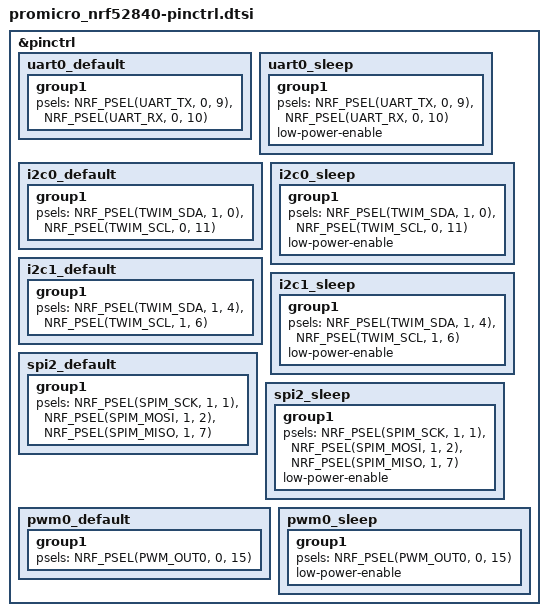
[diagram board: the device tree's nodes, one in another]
/*
 * Copyright (c) 2024 MASSDRIVER EI (massdriver.space)
 * SPDX-License-Identifier: Apache-2.0
 */

&pinctrl {
	uart0_default: uart0_default {
		group1 {
			psels = <NRF_PSEL(UART_TX, 0, 9)>,
				<NRF_PSEL(UART_RX, 0, 10)>;
		};
	};

	uart0_sleep: uart0_sleep {
		group1 {
			psels = <NRF_PSEL(UART_TX, 0, 9)>,
				<NRF_PSEL(UART_RX, 0, 10)>;
			low-power-enable;
		};
	};

	i2c0_default: i2c0_default {
		group1 {
			psels = <NRF_PSEL(TWIM_SDA, 1, 0)>,
				<NRF_PSEL(TWIM_SCL, 0, 11)>;
		};
	};

	i2c0_sleep: i2c0_sleep {
		group1 {
			psels = <NRF_PSEL(TWIM_SDA, 1, 0)>,
				<NRF_PSEL(TWIM_SCL, 0, 11)>;
			low-power-enable;
		};
	};

	i2c1_default: i2c1_default {
		group1 {
			psels = <NRF_PSEL(TWIM_SDA, 1, 4)>,
				<NRF_PSEL(TWIM_SCL, 1, 6)>;
		};
	};

	i2c1_sleep: i2c1_sleep {
		group1 {
			psels = <NRF_PSEL(TWIM_SDA, 1, 4)>,
				<NRF_PSEL(TWIM_SCL, 1, 6)>;
			low-power-enable;
		};
	};

	spi2_default: spi2_default {
		group1 {
			psels = <NRF_PSEL(SPIM_SCK, 1, 1)>,
				<NRF_PSEL(SPIM_MOSI, 1, 2)>,
				<NRF_PSEL(SPIM_MISO, 1, 7)>;
		};
	};

	spi2_sleep: spi2_sleep {
		group1 {
			psels = <NRF_PSEL(SPIM_SCK, 1, 1)>,
				<NRF_PSEL(SPIM_MOSI, 1, 2)>,
				<NRF_PSEL(SPIM_MISO, 1, 7)>;
			low-power-enable;
		};
	};

	pwm0_default: pwm0_default {
		group1 {
			psels = <NRF_PSEL(PWM_OUT0, 0, 15)>;
		};
	};

	pwm0_sleep: pwm0_sleep {
		group1 {
			psels = <NRF_PSEL(PWM_OUT0, 0, 15)>;
			low-power-enable;
		};
	};
};
